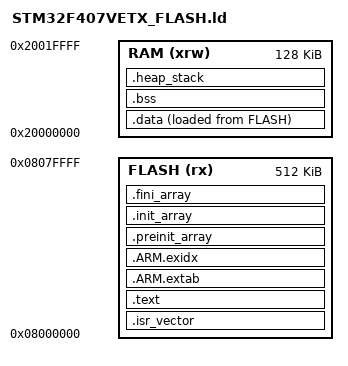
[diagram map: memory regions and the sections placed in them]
ENTRY(Reset_Handler)

MEMORY
{
    FLASH (rx) : ORIGIN = 0x08000000, LENGTH = 512K
    RAM (xrw) : ORIGIN = 0x20000000, LENGTH = 128K
}

_estack = ORIGIN(RAM) + LENGTH(RAM);
_Min_Heap_Size = 0x200;
_Min_Stack_Size = 0x400;

SECTIONS
{
    .isr_vector :
    {
        . = ALIGN(512);
        KEEP(*(.isr_vector))
    } > FLASH

    .text :
    {
        . = ALIGN(4);
        *(.text .text.*)
        *(.rodata .rodata.*)
        KEEP(*(.init))
        KEEP(*(.fini))
        . = ALIGN(4);
        _etext = .;
    } > FLASH

    .ARM.extab : { *(.ARM.extab* .gnu.linkonce.armextab.*) } > FLASH
    .ARM.exidx :
    {
        __exidx_start = .;
        *(.ARM.exidx*)
        __exidx_end = .;
    } > FLASH

    .preinit_array (READONLY) :
    {
        PROVIDE_HIDDEN(__preinit_array_start = .);
        KEEP(*(.preinit_array*))
        PROVIDE_HIDDEN(__preinit_array_end = .);
    } > FLASH
    .init_array (READONLY) :
    {
        PROVIDE_HIDDEN(__init_array_start = .);
        KEEP(*(SORT(.init_array.*)))
        KEEP(*(.init_array))
        PROVIDE_HIDDEN(__init_array_end = .);
    } > FLASH
    .fini_array (READONLY) :
    {
        PROVIDE_HIDDEN(__fini_array_start = .);
        KEEP(*(SORT(.fini_array.*)))
        KEEP(*(.fini_array))
        PROVIDE_HIDDEN(__fini_array_end = .);
    } > FLASH

    _sidata = LOADADDR(.data);
    .data :
    {
        . = ALIGN(4);
        _sdata = .;
        *(.data .data.*)
        *(.RamFunc .RamFunc.*)
        . = ALIGN(4);
        _edata = .;
    } > RAM AT > FLASH

    .bss (NOLOAD) :
    {
        . = ALIGN(4);
        _sbss = .;
        *(.bss .bss.*)
        *(COMMON)
        . = ALIGN(4);
        _ebss = .;
    } > RAM

    .heap_stack (NOLOAD) :
    {
        . = ALIGN(8);
        PROVIDE(end = .);
        PROVIDE(_end = .);
        . += _Min_Heap_Size;
        . += _Min_Stack_Size;
        . = ALIGN(8);
    } > RAM

    .ARM.attributes 0 : { *(.ARM.attributes) }
}

ASSERT(ADDR(.isr_vector) == ORIGIN(FLASH), "Vector table must start at flash base")
ASSERT(SIZEOF(.isr_vector) == 392, "STM32F407 vector table must contain 98 entries")
ASSERT(_ebss + _Min_Heap_Size + _Min_Stack_Size <= _estack, "RAM heap and stack overflow")
